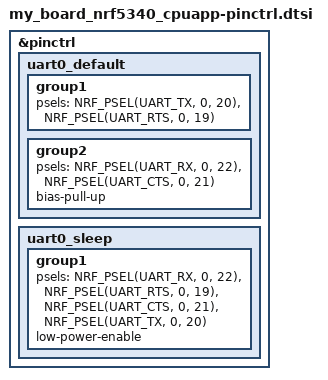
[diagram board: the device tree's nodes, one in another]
&pinctrl {
	uart0_default: uart0_default {
		group1 {
			psels = <NRF_PSEL(UART_TX, 0, 20)>,
				<NRF_PSEL(UART_RTS, 0, 19)>;
		};

		group2 {
			psels = <NRF_PSEL(UART_RX, 0, 22)>,
				<NRF_PSEL(UART_CTS, 0, 21)>;
			bias-pull-up;
		};
	};

	uart0_sleep: uart0_sleep {
		group1 {
			psels = <NRF_PSEL(UART_RX, 0, 22)>,
				<NRF_PSEL(UART_RTS, 0, 19)>,
				<NRF_PSEL(UART_CTS, 0, 21)>,
				<NRF_PSEL(UART_TX, 0, 20)>;
			low-power-enable;
		};
	};
};
